# msradc_reva register map
Registers are 32-bit, read-write, no defined reset value unless marked. A register's access mark holds for its fields unless they carry their own. Offsets are from the block's base; lines under a group give offsets from that group; [hi:lo] are bit positions; {n}, {i} and the like mark numbered series; 'fields as' and 'values as' point back to an identical list; <NAME> marks a mode.

## Memory map
0x4002B000 MSRADC size 0x1000 — Magnetic Strip Reader - 9 bit ADC

## Interrupts
20 ADC9 (MSRADC) — ADC IRQ

## MSRADC — Magnetic Strip Reader - 9 bit ADC
Base 0x4002B000
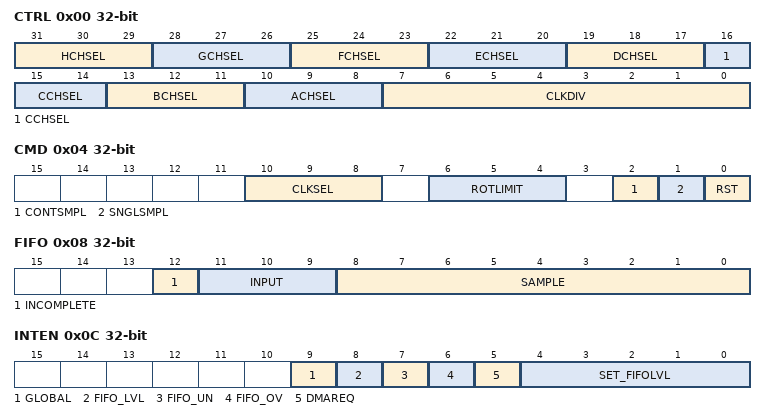
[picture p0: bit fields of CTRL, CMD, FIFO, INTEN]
0x00 CTRL — ADC Control
  [31:29] HCHSEL — H Channel ADC Input Pin Selection.
    0=invalid; 1=CH1_IN; 2=CH2_IN; 3=CH3_IN
  [28:26] GCHSEL — G Channel ADC Input Pin Selection.
    0=invalid; 1=CH1_IN; 2=CH2_IN; 3=CH3_IN
  [25:23] FCHSEL — F Channel ADC Input Pin Selection.
    0=invalid; 1=CH1_IN; 2=CH2_IN; 3=CH3_IN
  [22:20] ECHSEL — E Channel ADC Input Pin Selection.
    0=invalid; 1=CH1_IN; 2=CH2_IN; 3=CH3_IN
  [19:17] DCHSEL — D Channel ADC Input Pin Selection.
    0=invalid; 1=CH1_IN; 2=CH2_IN; 3=CH3_IN
  [16:14] CCHSEL — C Channel ADC Input Pin Selection.
    0=invalid; 1=CH1_IN; 2=CH2_IN; 3=CH3_IN
  [13:11] BCHSEL — B Channel ADC Input Pin Selection.
    0=invalid; 1=CH1_IN; 2=CH2_IN; 3=CH3_IN
  [10:8] ACHSEL — A Channel ADC Input Pin Selection.
    0=invalid; 1=CH1_IN; 2=CH2_IN; 3=CH3_IN
  [7:0] CLKDIV — ADC Clock Divider.
0x04 CMD — MSRADC Command
  [10:8] CLKSEL — Clock Select.
    0=3_samples; 1=5_samples; 2=4_samples; 3=8_samples; 4=16_samples; 5=32_samples; 6=64_samples; 7=128_samples
  [6:4] ROTLIMIT — Rotation Limit.
    0=1_channel; {v}={v+1}_channels (v=1..7)
  [2] CONTSMPL — Continuous Sample Mode Enable.
  [1] SNGLSMPL — Single Sample Mode.
  [0] RST — ADC Reset.
0x08 FIFO — ADC FIFO
  [12] INCOMPLETE ro — ADC Incomplete.
  [11:9] INPUT ro — ADC Sample Pin
    0=invalid; {v}=CH{v}_IN (v=1..7)
  [8:0] SAMPLE ro — ADC Converted Sample Data Output
0x0C INTEN — ADC Interrupt Enable Register
  [9] GLOBAL — ADC Global Interrupt Enable.
  [8] FIFO_LVL — FIFO Level Interrupt Enable.
  [7] FIFO_UN — FIFO Underflow Interrupt Enable.
  [6] FIFO_OV — FIFO Overflow Interrupt Enable.
  [5] DMAREQ — DMA Request Enable.
  [4:0] SET_FIFOLVL — Set FIFO Interrupt Level.
    {v}=at_least_{v+1} (v=0..15)
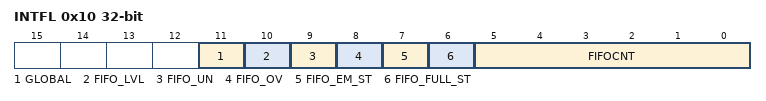
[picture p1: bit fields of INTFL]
0x10 INTFL — ADC Interrupt Flag Register.
  [11] GLOBAL ro — ADC Global Interrupt Flag.
  [10] FIFO_LVL ro — FIFO Level Status.
  [9] FIFO_UN ro — FIFO Underflow Status.
  [8] FIFO_OV ro — FIFO Overflow Status.
  [7] FIFO_EM_ST ro — FIFO Empty Status.
  [6] FIFO_FULL_ST ro — FIFO Full Status.
  [5:0] FIFOCNT ro — FIFO Count.
